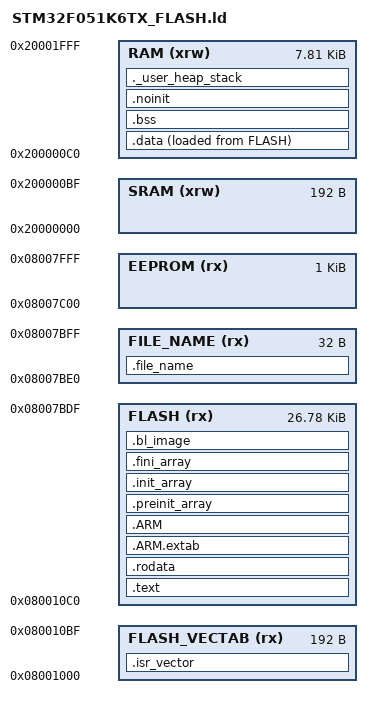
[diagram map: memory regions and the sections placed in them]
/**
 ******************************************************************************
 * @file      LinkerScript.ld
 * @author    Auto-generated by STM32CubeIDE
 * @brief     Linker script for STM32F051K6Tx Device from STM32F0 series
 *                      32Kbytes FLASH
 *                      8Kbytes RAM
 *
 *            Set heap size, stack size and stack location according
 *            to application requirements.
 *
 *            Set memory bank area and size if external memory is used
 ******************************************************************************
 * @attention
 *
 * <h2><center>&copy; Copyright (c) 2020 STMicroelectronics.
 * All rights reserved.</center></h2>
 *
 * This software component is licensed by ST under BSD 3-Clause license,
 * the "License"; You may not use this file except in compliance with the
 * License. You may obtain a copy of the License at:
 *                        opensource.org/licenses/BSD-3-Clause
 *
 ******************************************************************************
 */

/* Entry Point */
ENTRY(Reset_Handler)

/* Highest address of the user mode stack */
_estack = ORIGIN(RAM) + LENGTH(RAM);	/* end of "RAM" Ram type memory */

/* App path does not use malloc; drop heap reservation on the F051. */
_Min_Heap_Size = 0x0 ;		/* no heap */
_Min_Stack_Size = 0x400 ;	/* required amount of stack */

/* Memories definition */

MEMORY
{
  SRAM          (xrw) : ORIGIN = 0x20000000, LENGTH = 192
  RAM           (xrw) : ORIGIN = 0x200000C0, LENGTH = 8K - 192
  FLASH_VECTAB  (rx)  : ORIGIN = 0x08001000, LENGTH = 192
  FLASH         (rx)  : ORIGIN = ORIGIN(FLASH_VECTAB) + LENGTH(FLASH_VECTAB), LENGTH = 27K - 32 - LENGTH(FLASH_VECTAB)
  EEPROM        (rx)  : ORIGIN = 0x08007C00, LENGTH = 1K
  FILE_NAME     (rx)  : ORIGIN = ORIGIN(EEPROM) - 32, LENGTH = 32
}

/* Sections */
SECTIONS
{
  /* The startup code into "FLASH" Rom type memory */
  .isr_vector :
  {
    . = ALIGN(4);
    KEEP(*(.isr_vector)) /* Startup code */
    . = ALIGN(4);
  } >FLASH_VECTAB

  /* The program code and other data into "FLASH" Rom type memory */
  .text :
  {
    . = ALIGN(4);
    *(.text)           /* .text sections (code) */
    *(.text*)          /* .text* sections (code) */
    *(.glue_7)         /* glue arm to thumb code */
    *(.glue_7t)        /* glue thumb to arm code */
    *(.eh_frame)

    KEEP (*(.init))
    KEEP (*(.fini))

    . = ALIGN(4);
    _etext = .;        /* define a global symbols at end of code */
  } >FLASH
  /* Constant data into "FLASH" Rom type memory */
  .rodata :
  {
    . = ALIGN(4);
    *(.rodata)         /* .rodata sections (constants, strings, etc.) */
    *(.rodata*)        /* .rodata* sections (constants, strings, etc.) */
    . = ALIGN(4);
  } >FLASH

  .ARM.extab   : { 
    . = ALIGN(4);
    *(.ARM.extab* .gnu.linkonce.armextab.*)
    . = ALIGN(4);
  } >FLASH
  
  .ARM : {
    . = ALIGN(4);
    __exidx_start = .;
    *(.ARM.exidx*)
    __exidx_end = .;
    . = ALIGN(4);
  } >FLASH

  .preinit_array     :
  {
    . = ALIGN(4);
    PROVIDE_HIDDEN (__preinit_array_start = .);
    KEEP (*(.preinit_array*))
    PROVIDE_HIDDEN (__preinit_array_end = .);
    . = ALIGN(4);
  } >FLASH
  
  .init_array :
  {
    . = ALIGN(4);
    PROVIDE_HIDDEN (__init_array_start = .);
    KEEP (*(SORT(.init_array.*)))
    KEEP (*(.init_array*))
    PROVIDE_HIDDEN (__init_array_end = .);
    . = ALIGN(4);
  } >FLASH
  
  .fini_array :
  {
    . = ALIGN(4);
    PROVIDE_HIDDEN (__fini_array_start = .);
    KEEP (*(SORT(.fini_array.*)))
    KEEP (*(.fini_array*))
    PROVIDE_HIDDEN (__fini_array_end = .);
    . = ALIGN(4);
  } >FLASH

  /* Bootloader image embedded for the app-side bootloader update (Src/bl_image.S).
     Empty unless the build defines EMBED_BOOTLOADER. Kept in its own output
     section for two reasons: the 4 KiB blob stays attributable in the map and
     the size gate instead of disappearing into .rodata, and the bounds symbols
     give the asserts at the end of this file something to test. Placed last in
     FLASH so it does not split the code and rodata it has nothing to do with. */
  .bl_image :
  {
    . = ALIGN(4);
    _bl_image_start = .;
    KEEP (*(.bl_image))
    . = ALIGN(4);
    _bl_image_end = .;
  } >FLASH

  /* The file name */
  .file_name :
  {
    . = ALIGN(4);
	KEEP (*(.file_name))
    . = ALIGN(4);
  } >FILE_NAME


  /* Used by the startup to initialize data */
  _sidata = LOADADDR(.data);

  /* Initialized data sections into "RAM" Ram type memory */
  .data :
  {
    . = ALIGN(4);
    _sdata = .;        /* create a global symbol at data start */
    *(.ramfunc)        /* functions executed from RAM, copied by startup data init */
    *(.ramfunc*)
    *(.data)           /* .data sections */
    *(.data*)          /* .data* sections */

    . = ALIGN(4);
    _edata = .;        /* define a global symbol at data end */

  } >RAM AT> FLASH

  /* Uninitialized data section into "RAM" Ram type memory */
  . = ALIGN(4);
  .bss :
  {
    /* This is used by the startup in order to initialize the .bss section */
    _sbss = .;         /* define a global symbol at bss start */
    __bss_start__ = _sbss;
    *(.bss)
    *(.bss*)
    *(COMMON)

    . = ALIGN(4);
    _ebss = .;         /* define a global symbol at bss end */
    __bss_end__ = _ebss;
  } >RAM

  /* Survives NVIC_SystemReset (not zeroed by startup); used for post-reset boot sound */
  .noinit (NOLOAD) :
  {
    . = ALIGN(4);
    *(.noinit)
    *(.noinit*)
    . = ALIGN(4);
  } >RAM

  /* User_heap_stack section, used to check that there is enough "RAM" Ram  type memory left */
  ._user_heap_stack :
  {
    . = ALIGN(8);
    PROVIDE ( end = . );
    PROVIDE ( _end = . );
    . = . + _Min_Heap_Size;
    . = . + _Min_Stack_Size;
    . = ALIGN(8);
  } >RAM

  /* Remove information from the compiler libraries */
  /DISCARD/ :
  {
    libc.a ( * )
    libm.a ( * )
    libgcc.a ( * )
  }

  .ARM.attributes 0 : { *(.ARM.attributes) }
}

/* The embedded bootloader image is written over the bootloader region, which runs
   from the start of flash up to the app at ORIGIN(FLASH_VECTAB). Both properties
   below are structurally true today - the app links above FLASH_VECTAB and the
   image is padded to the region size in Src/bl_image.S - but they are the two
   mistakes that brick a board rather than fail a test, so a future MEMORY edit
   should break the link instead. Size 0 is the non-embedding build. */
_bl_region_start = 0x08000000;
_bl_region_size  = ORIGIN(FLASH_VECTAB) - _bl_region_start;

ASSERT(_bl_image_end - _bl_image_start == 0 ||
       _bl_image_end - _bl_image_start == _bl_region_size,
       "embedded bootloader image must be exactly the size of the bootloader region")

ASSERT(_bl_image_start >= ORIGIN(FLASH_VECTAB),
       "embedded bootloader image must not live inside the region it erases")
